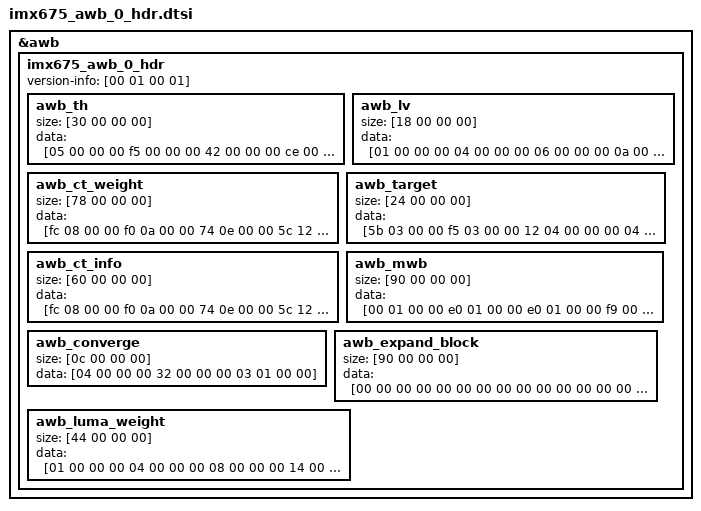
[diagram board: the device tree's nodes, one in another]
/*
 * Novatek Ltd. NA51055 BSP part of dts
 *
 * Cortex-A9
 *
 */

&awb {
	imx675_awb_0_hdr {
		version-info = [00 01 00 01];
		awb_th {
			size = [30 00 00 00];
			data = [05 00 00 00 f5 00 00 00 42 00 00 00 ce 00 00 00 e1 ff ff ff 62 00 00 00 29 00 00 00 89 00 00 00 1a 00 00 00 49 00 00 00 14 00 00 00 2a 00 00 00];
		};
		awb_lv {
			size = [18 00 00 00];
			data = [01 00 00 00 04 00 00 00 06 00 00 00 0a 00 00 00 0c 00 00 00 1a 00 00 00];
		};
		awb_ct_weight {
			size = [78 00 00 00];
			data = [fc 08 00 00 f0 0a 00 00 74 0e 00 00 5c 12 00 00 64 19 00 00 f8 2a 00 00 40 03 00 00 5b 03 00 00 b8 03 00 00 f5 03 00 00 12 04 00 00 55 04 00 00 01 00 00 00 01 00 00 00 01 00 00 00 05 00 00 00 05 00 00 00 05 00 00 00 01 00 00 00 01 00 00 00 01 00 00 00 04 00 00 00 04 00 00 00 04 00 00 00 01 00 00 00 01 00 00 00 01 00 00 00 01 00 00 00 01 00 00 00 01 00 00 00];
		};
		awb_target {
			size = [24 00 00 00];
			data = [5b 03 00 00 f5 03 00 00 12 04 00 00 00 04 00 00 e8 03 00 00 e8 03 00 00 00 04 00 00 24 04 00 00 24 04 00 00];
		};
		awb_ct_info {
			size = [60 00 00 00];
			data = [fc 08 00 00 f0 0a 00 00 74 0e 00 00 5c 12 00 00 64 19 00 00 f8 2a 00 00 02 01 00 00 18 01 00 00 8c 01 00 00 cb 01 00 00 e4 01 00 00 37 02 00 00 00 01 00 00 00 01 00 00 00 01 00 00 00 01 00 00 00 01 00 00 00 01 00 00 c3 02 00 00 9f 02 00 00 57 02 00 00 ea 01 00 00 b4 01 00 00 66 01 00 00];
		};
		awb_mwb {
			size = [90 00 00 00];
			data = [00 01 00 00 e0 01 00 00 e0 01 00 00 f9 00 00 00 1d 01 00 00 00 01 00 00 00 01 00 00 00 01 00 00 00 01 00 00 00 01 00 00 00 01 00 00 00 01 00 00 00 01 00 00 00 01 00 00 00 01 00 00 00 01 00 00 00 01 00 00 00 01 00 00 00 01 00 00 00 01 00 00 00 01 00 00 00 01 00 00 00 01 00 00 00 01 00 00 00 01 00 00 79 01 00 00 40 01 00 00 47 03 00 00 26 03 00 00 00 01 00 00 00 01 00 00 00 01 00 00 00 01 00 00 00 01 00 00 00 01 00 00 00 01 00 00];
		};
		awb_converge {
			size = [0c 00 00 00];
			data = [04 00 00 00 32 00 00 00 03 01 00 00];
		};
		awb_expand_block {
			size = [90 00 00 00];
			data = [00 00 00 00 00 00 00 00 00 00 00 00 00 00 00 00 03 00 00 00 02 00 00 00 06 00 00 00 06 00 00 00 08 00 00 00 04 00 00 00 0a 00 00 00 0a 00 00 00 05 00 00 00 05 00 00 00 05 00 00 00 05 00 00 00 b4 00 00 00 b4 00 00 00 f5 00 00 00 f5 00 00 00 6e 00 00 00 80 00 00 00 5b 00 00 00 72 00 00 00 83 00 00 00 8c 00 00 00 69 00 00 00 80 00 00 00 07 00 00 00 22 00 00 00 12 00 00 00 20 00 00 00 20 00 00 00 43 00 00 00 20 00 00 00 cb ff ff ff];
		};
		awb_luma_weight {
			size = [44 00 00 00];
			data = [01 00 00 00 04 00 00 00 08 00 00 00 14 00 00 00 20 00 00 00 c0 00 00 00 d0 00 00 00 e0 00 00 00 f0 00 00 00 01 00 00 00 01 00 00 00 01 00 00 00 01 00 00 00 01 00 00 00 01 00 00 00 01 00 00 00 01 00 00 00];
		};
	};
};
